# M461 register map
File version: 2.0.2.2
Registers are 32-bit, read-write, reset 0x0 unless marked. A register's access mark holds for its fields unless they carry their own. Offsets are from the block's base; [hi:lo] are bit positions; {n}, {i} and the like mark numbered series.

## DMAA — DMA Controller
Base 0x4004C000
Same registers: DMAB 0x4004D000, DMAC 0x4004E000
0x00 STATUS ro reset 0x101F0000 — DMA Status Register
  [0] MASTER_ENABLE
0x04 CFG wo reset not defined — DMA Configuration Register
  [0] MASTER_ENABLE
0x08 CTRLBASEPTR — DMA Control Data Base Pointer Register
  [31:10] CTRL_BASE_PTR
0x0C ALTCTRLBASEPTR ro — DMA Channel Alternate Control Data Base Pointer Register
  [31:0] ALT_CTRL_BASE_PTR
0x14 CHNLSWREQUEST wo reset not defined — DMA Channel Software Request Register
  [31:0] CHNL_SW_REQUEST
0x18 CHNLUSEBURSTSET — DMA Channel Useburst Set Register
  [31:0] CHNL_USEBURST_SET
0x1C CHNLUSEBURSTCLR wo reset not defined — DMA Channel Useburst Clear Register
  [31:0] CHNL_USEBURST_CLR
0x20 CHNLREQMASKSET — DMA Channel Request Mask Set Register
  [31:0] CHNL_REQ_MASK_SET
0x24 CHNLREQMASKCLR wo reset not defined — DMA Channel Request Mask Clear Register
  [31:0] CHNL_REQ_MASK_CLR
0x28 CHNLENABLESET — DMA Channel Enable Set Register
  [31:0] CHNL_ENABLE_SET
0x2C CHNLENABLECLR wo reset not defined — DMA Channel Enable Clear Register
  [31:0] CHNL_ENABLE_CLR
0x30 CHNLPRIALTSET — DMA Channel Primary-Alternate Set Register
  [31:0] CHNL_PRI_ALT_SET
0x34 CHNLPRIALTCLR wo reset not defined — DMA Channel Primary-Alternate Clear Register
  [31:0] CHNL_PRI_ALT_CLR
0x38 CHNLPRIORITYSET — DMA Channel Priority Set Register
  [31:0] CHNL_PRIORITY_SET
0x3C CHNLPRIORITYCLR wo reset not defined — DMA Channel Priority Clear Register
  [31:0] CHNL_PRIORITY_CLR
0x4C ERRCLR — DMA Bus Error Clear Register
  [0] ERR_CLR

## DMAIF — DMA Interrupt Flag
Base 0x4005F000
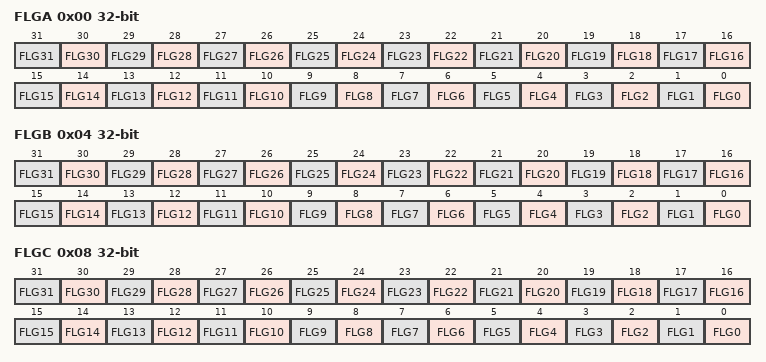
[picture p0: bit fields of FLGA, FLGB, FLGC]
0x00 FLGA ro — DMA Flag Register A
  [n] FLG{n} (n=0..31)
0x04 FLGB ro — DMA Flag Register B
  [n] FLG{n} (n=0..31)
0x08 FLGC ro — DMA Flag Register C
  [n] FLG{n} (n=0..31)

## AD — 12bit A_D Converter
Base 0x40050000
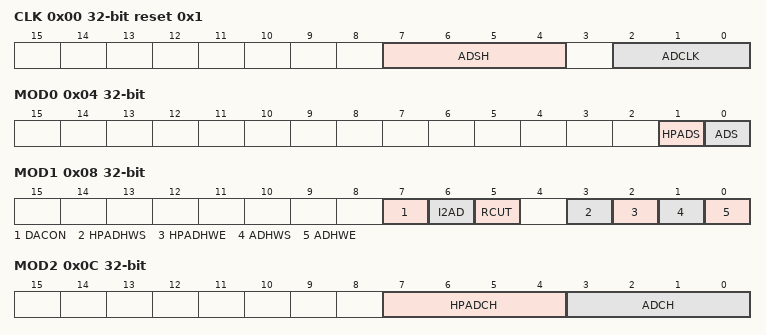
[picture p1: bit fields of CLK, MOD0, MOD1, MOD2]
0x00 CLK reset 0x1 — Conversion Clock Setting Register
  [7:4] ADSH, [2:0] ADCLK
0x04 MOD0 wo — Mode Control Register0
  [1] HPADS, [0] ADS
0x08 MOD1 — Mode Control Register1
  [7] DACON, [6] I2AD, [5] RCUT, [3] HPADHWS, [2] HPADHWE, [1] ADHWS, [0] ADHWE
0x0C MOD2 — Mode Control Register2
  [7:4] HPADCH, [3:0] ADCH
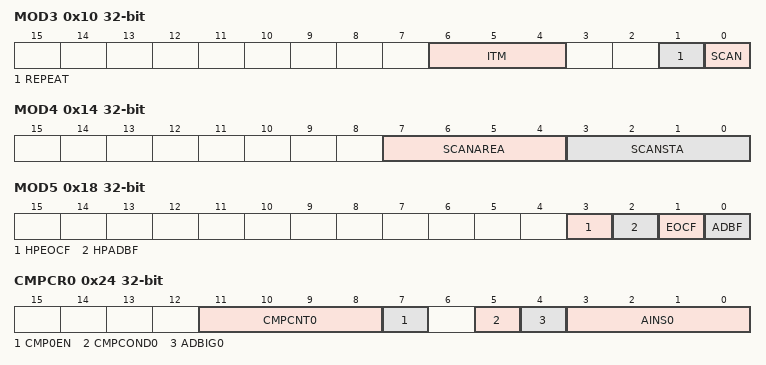
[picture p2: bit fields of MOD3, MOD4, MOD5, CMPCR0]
0x10 MOD3 — Mode Control Register3
  [6:4] ITM, [1] REPEAT, [0] SCAN
0x14 MOD4 — Mode Control Register4
  [7:4] SCANAREA, [3:0] SCANSTA
0x18 MOD5 ro — Mode Control Register5
  [3] HPEOCF, [2] HPADBF, [1] EOCF, [0] ADBF
0x1C MOD6 wo — Mode Control Register6
  [1:0] ADRST
0x24 CMPCR0 — Monitoring Interrupt Control Register0
  [11:8] CMPCNT0, [7] CMP0EN, [5] CMPCOND0, [4] ADBIG0, [3:0] AINS0
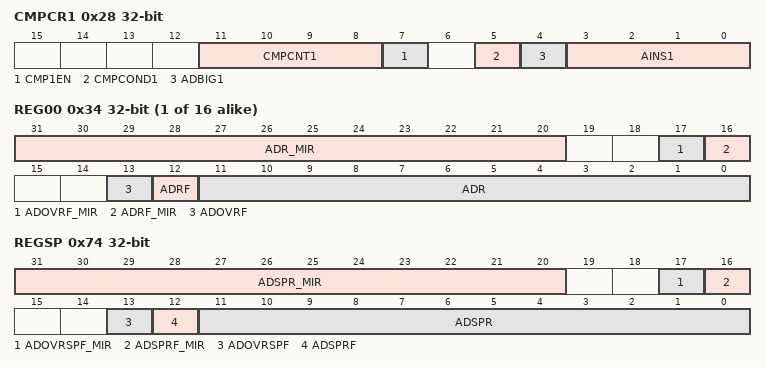
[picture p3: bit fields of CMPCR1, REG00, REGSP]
0x28 CMPCR1 — Monitoring Interrupt Control Register1
  [11:8] CMPCNT1, [7] CMP1EN, [5] CMPCOND1, [4] ADBIG1, [3:0] AINS1
0x2C CMP0 — Conversion Result Compare Register0
  [11:0] AD0CMP
0x30 CMP1 — Conversion Result Compare Register1
  [11:0] AD1CMP
{0x34+4i} REG{i:02} ro (i=0..15) — Conversion Result Store Register{i}
  [31:20] ADR_MIR, [17] ADOVRF_MIR, [16] ADRF_MIR, [13] ADOVRF, [12] ADRF, [11:0] ADR
0x74 REGSP ro — Highest Priority Conversion Result Store Register
  [31:20] ADSPR_MIR, [17] ADOVRSPF_MIR, [16] ADSPRF_MIR, [13] ADOVRSPF, [12] ADSPRF, [11:0] ADSPR

## EXB — External Bus Interface(EXB)
Base 0x4005C000
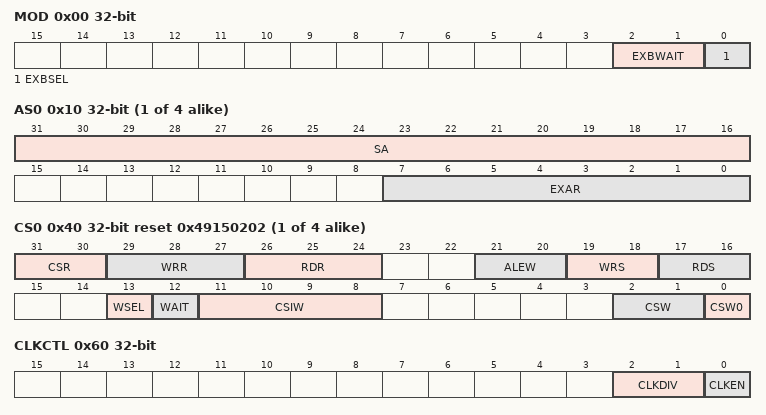
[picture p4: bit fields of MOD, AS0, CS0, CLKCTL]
0x00 MOD — External Bus Mode Control Register
  [2:1] EXBWAIT, [0] EXBSEL
{0x10+4i} AS{i} (i=0..3) — External Bus Base Address and CS Space setting Register {i}
  [31:16] SA, [7:0] EXAR
{0x40+4i} CS{i} reset 0x49150202 (i=0..3) — Chip Select and Wait Controller Register {i}
  [31:30] CSR, [29:27] WRR, [26:24] RDR, [21:20] ALEW, [19:18] WRS, [17:16] RDS, [13] WSEL, [12] WAIT, [11:8] CSIW, [2:1] CSW, [0] CSW0
0x60 CLKCTL — Clock output controlRegister
  [2:1] CLKDIV, [0] CLKEN

## ADILV — ADC infterface Register
Base 0x40066000
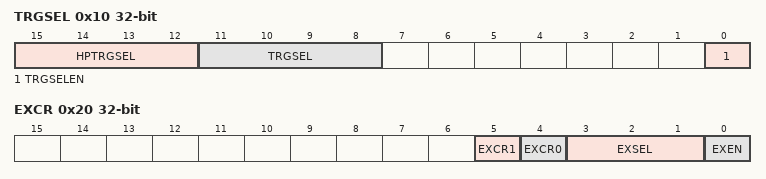
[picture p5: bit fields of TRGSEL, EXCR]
0x10 TRGSEL — Trigger Selection Register
  [15:12] HPTRGSEL, [11:8] TRGSEL, [0] TRGSELEN
0x20 EXCR — Extencion channel setting Register
  [5] EXCR1, [4] EXCR0, [3:1] EXSEL, [0] EXEN
